# MKM14ZA5 register map
Vendor: Freescale Semiconductor, Inc.; Series: Kinetis_M; File version: 1.6
CPU: CM0PLUS r0p0, little endian, no MPU, no FPU, VTOR, 2 interrupt priority bits
Registers are 8-bit, read-write, reset 0x0 unless marked. A register's access mark holds for its fields unless they carry their own. Offsets are from the block's base; [hi:lo] are bit positions; {n}, {i} and the like mark numbered series; 'fields as' and 'values as' point back to an identical list.

## MTB — Micro Trace Buffer
Base 0xF0000000; register names take the prefix MTB_
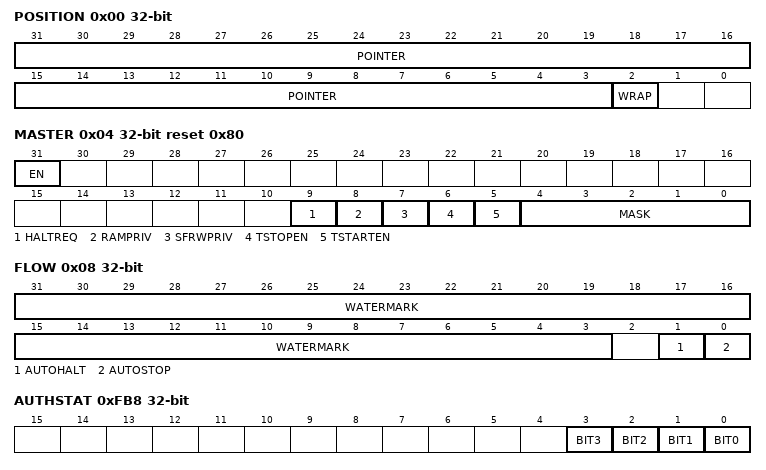
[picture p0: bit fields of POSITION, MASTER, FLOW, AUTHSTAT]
0x00 POSITION 32-bit (reset mask 0x3) — MTB Position Register
  [31:3] POINTER — Trace Packet Address Pointer[28:0]
  [2] WRAP
0x04 MASTER 32-bit reset 0x80 (reset mask 0xFFFFFFE0) — MTB Master Register
  [31] EN — Main Trace Enable
  [9] HALTREQ — Halt Request
  [8] RAMPRIV — RAM Privilege
  [7] SFRWPRIV — Special Function Register Write Privilege
  [6] TSTOPEN — Trace Stop Input Enable
  [5] TSTARTEN — Trace Start Input Enable
  [4:0] MASK
0x08 FLOW 32-bit (reset mask 0x4) — MTB Flow Register
  [31:3] WATERMARK — WATERMARK[28:0]
  [1] AUTOHALT
  [0] AUTOSTOP
0x0C BASE 32-bit ro reset not defined — MTB Base Register
  [31:0] BASEADDR
0xF00 MODECTRL 32-bit ro — Integration Mode Control Register
0xFA0 TAGSET 32-bit ro — Claim TAG Set Register
0xFA4 TAGCLEAR 32-bit ro — Claim TAG Clear Register
0xFB0 LOCKACCESS 32-bit ro
0xFB4 LOCKSTAT 32-bit ro — Lock Status Register
0xFB8 AUTHSTAT 32-bit ro — Authentication Status Register
  [n] BIT{n} (n=0..3)
0xFBC DEVICEARCH 32-bit ro reset 0x47700A31 — Device Architecture Register
0xFC8 DEVICECFG 32-bit ro — Device Configuration Register
0xFCC DEVICETYPID 32-bit ro reset 0x31 — Device Type Identifier Register
0xFD0 PERIPHID{x} (x=4,5,6,7,0,1,2,3; step 0x4) 32-bit ro reset not defined — Peripheral ID Register
  [31:0] PERIPHID
{0xFF0+4i} COMPID{i} (i=0..3) 32-bit ro reset not defined — Component ID Register
  [31:0] COMPID — Component ID

## MTBDWT — MTB data watchpoint and trace
Base 0xF0001000; register names take the prefix MTBDWT_
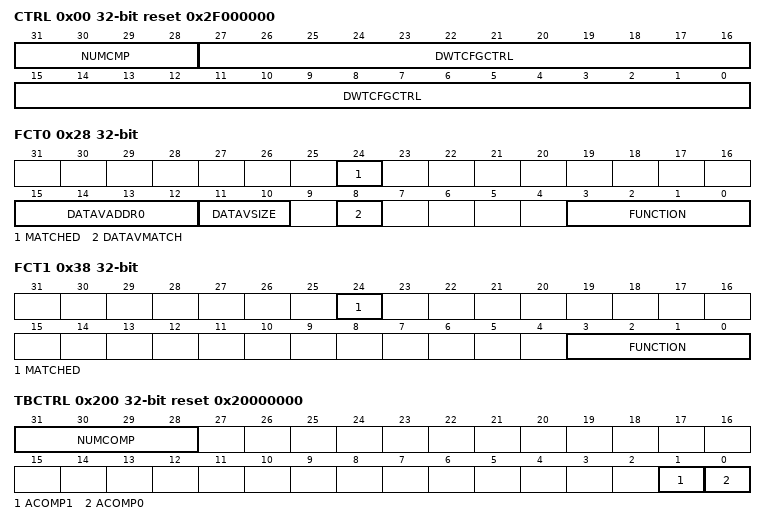
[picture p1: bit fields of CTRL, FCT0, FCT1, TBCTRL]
0x00 CTRL 32-bit ro reset 0x2F000000 — MTB DWT Control Register
  [31:28] NUMCMP — Number of comparators
  [27:0] DWTCFGCTRL — DWT configuration controls
{0x20+0x10*i} COMP{i} (i=0..1) 32-bit — MTB_DWT Comparator Register
  [31:0] COMP — Reference value for comparison
{0x24+0x10*i} MASK{i} (i=0..1) 32-bit — MTB_DWT Comparator Mask Register
  [4:0] MASK
0x28 FCT0 32-bit — MTB_DWT Comparator Function Register 0
  [24] MATCHED ro — Comparator match
    0=No match; 1=Match occurred
  [15:12] DATAVADDR0 — Data Value Address 0
  [11:10] DATAVSIZE — Data Value Size
    0=Byte; 1=Halfword; 2=Word; 3=Reserved. Any attempts to use this value results in UNPREDICTABLE behavior.
  [8] DATAVMATCH — Data Value Match
    0=Perform address comparison; 1=Perform data value comparison
  [3:0] FUNCTION
    0=Disabled; 4=Instruction fetch; 5=Data operand read; 6=Data operand write; 7=Data operand (read + write)
0x38 FCT1 32-bit — MTB_DWT Comparator Function Register 1
  [24] MATCHED ro — Comparator match
    0=No match; 1=Match occurred
  [3:0] FUNCTION
    values as FCT0.FUNCTION
0x200 TBCTRL 32-bit reset 0x20000000 — MTB_DWT Trace Buffer Control Register
  [31:28] NUMCOMP ro — Number of Comparators
  [1] ACOMP1 — Action based on Comparator 1 match
    0=Trigger TSTOP based on the assertion of MTBDWT_FCT1[MATCHED]; 1=Trigger TSTART based on the assertion of MTBDWT_FCT1[MATCHED]
  [0] ACOMP0 — Action based on Comparator 0 match
    0=Trigger TSTOP based on the assertion of MTBDWT_FCT0[MATCHED]; 1=Trigger TSTART based on the assertion of MTBDWT_FCT0[MATCHED]
0xFC8 DEVICECFG 32-bit ro — Device Configuration Register
0xFCC DEVICETYPID 32-bit ro reset 0x4 — Device Type Identifier Register
0xFD0 PERIPHID{x} (x=4,5,6,7,0,1,2,3; step 0x4) 32-bit ro reset not defined — Peripheral ID Register
  [31:0] PERIPHID
{0xFF0+4i} COMPID{i} (i=0..3) 32-bit ro reset not defined — Component ID Register
  [31:0] COMPID — Component ID

## ROM — System ROM
Base 0xF0002000; register names take the prefix ROM_
{0x0+4i} ENTRY{i} (i=0..2) 32-bit ro reset not defined
  [31:0] ENTRY
0x0C TABLEMARK 32-bit ro — End of Table Marker Register
  [31:0] MARK
0xFCC SYSACCESS 32-bit ro reset 0x1 — System Access Register
0xFD0 PERIPHID{x} (x=4,5,6,7,0,1,2,3; step 0x4) 32-bit ro reset not defined — Peripheral ID Register
  [31:0] PERIPHID
{0xFF0+4i} COMPID{i} (i=0..3) 32-bit ro reset not defined — Component ID Register
  [31:0] COMPID — Component ID

## MCM — Core Platform Miscellaneous Control Module
Base 0xF0003000; register names take the prefix MCM_
0x08 PLASC 16-bit ro reset 0x7 — Crossbar Switch (AXBS) Slave Configuration
  [7:0] ASC — Each bit in the ASC field indicates whether there is a corresponding connection to the crossbar switch's slave input port.
    0=A bus slave connection to AXBS input port n is absent; 1=A bus slave connection to AXBS input port n is present
0x0A PLAMC 16-bit ro reset 0x5 — Crossbar Switch (AXBS) Master Configuration
  [7:0] AMC — Each bit in the AMC field indicates whether there is a corresponding connection to the AXBS master input port.
    0=A bus master connection to AXBS input port n is absent; 1=A bus master connection to AXBS input port n is present
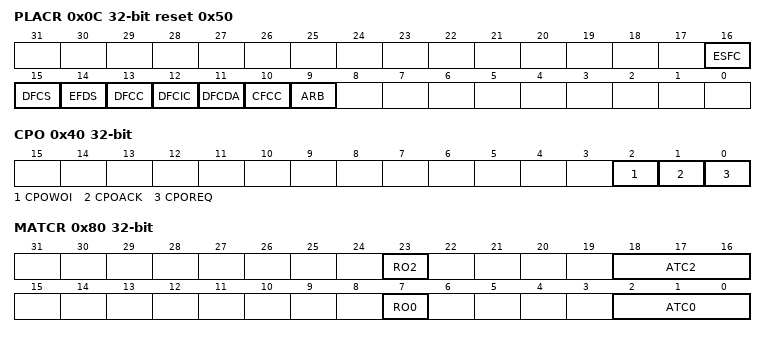
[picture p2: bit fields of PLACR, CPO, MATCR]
0x0C PLACR 32-bit reset 0x50 — Platform Control Register
  [16] ESFC — Enable Stalling Flash Controller
    0=Disable stalling flash controller when flash is busy; 1=Enable stalling flash controller when flash is busy
  [15] DFCS — Disable Flash Controller Speculation
    0=Enable flash controller speculation; 1=Disable flash controller speculation
  [14] EFDS — Enable Flash Data Speculation
    0=Disable flash data speculation; 1=Enable flash data speculation
  [13] DFCC — Disable Flash Controller Cache
    0=Enable flash controller cache; 1=Disable flash controller cache
  [12] DFCIC — Disable Flash Controller Instruction Caching
    0=Enable flash controller instruction caching; 1=Disable flash controller instruction caching
  [11] DFCDA — Disable Flash Controller Data Caching
    0=Enable flash controller data caching; 1=Disable flash controller data caching
  [10] CFCC wo — Clear Flash Controller Cache
  [9] ARB — Arbitration select
    0=Fixed-priority arbitration for the crossbar masters; 1=Round-robin arbitration for the crossbar masters
0x30 PID 32-bit — Process ID register
  [7:0] PID — M0_PID For MPU
    0=Reserved for privileged secure tasks
0x40 CPO 32-bit — Compute Operation Control Register
  [2] CPOWOI — Compute Operation Wake-up on Interrupt
    0=No effect; 1=When set, the CPOREQ is cleared on any interrupt or exception vector fetch
  [1] CPOACK ro — Compute Operation Acknowledge
    0=Compute operation entry has not completed or compute operation exit has completed; 1=Compute operation entry has completed or compute operation exit has not completed
  [0] CPOREQ — Compute Operation Request
    0=Request is cleared; 1=Request Compute Operation
0x80 MATCR 32-bit — Master Attribute Configuration Register
  [23] RO2 — Read-Only Master n
    0=Writes to the ATCn are allowed; 1=Writes to the ATCn are ignored
  [18:16] ATC2 — Attribute Configuration Master n
    0b00x=Master attributes are statically forced to {privileged, secure}; 2=Master attributes are statically forced to {user, secure}; 3=Master attributes are statically forced to {user, nonsecure}; 4=Enable master attribute {privileged or user} and statically force {secure}; 5=Enable master attribute {privileged or user} and statically force {nonsecure}; 0b11x=Enable master attribute {privileged or user, secure or nonsecure}
  [7] RO0 — Read-Only Master n
    values as RO2
  [2:0] ATC0 — Attribute Configuration Master n
    values as ATC2
